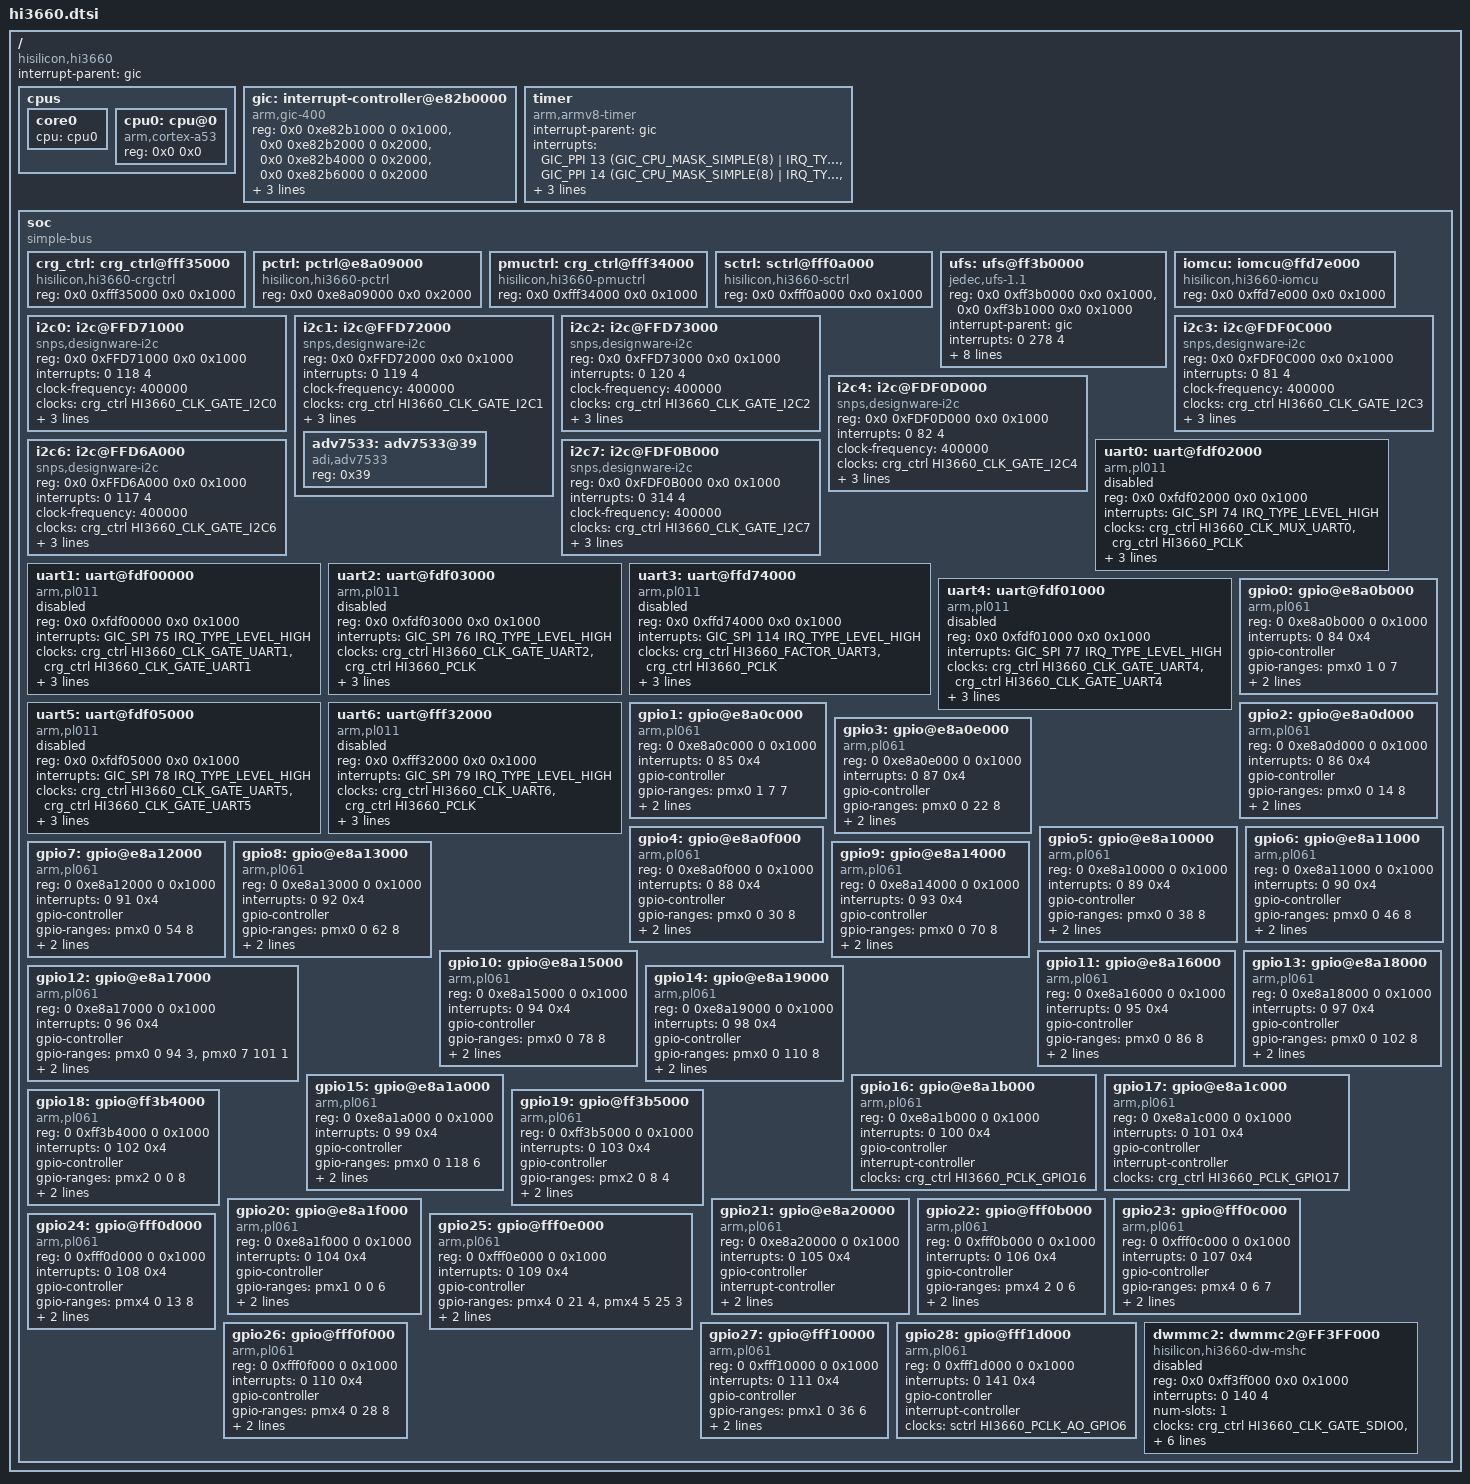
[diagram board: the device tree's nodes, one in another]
/*
 * dts file for Hisilicon Hi3660 SoC
 *
 * Copyright (C) 2016, Hisilicon Ltd.
 */

#include <dt-bindings/interrupt-controller/arm-gic.h>
#include <dt-bindings/clock/hi3660-clock.h>

/ {
	compatible = "hisilicon,hi3660";
	interrupt-parent = <&gic>;
	#address-cells = <2>;
	#size-cells = <2>;

	cpus {
		#address-cells = <2>;
		#size-cells = <0>;

		core0 {
			cpu = <&cpu0>;
		};

		cpu0: cpu@0 {
			compatible = "arm,cortex-a53", "arm,armv8";
			device_type = "cpu";
			reg = <0x0 0x0>;
		};
	};

	gic: interrupt-controller@e82b0000 {
		compatible = "arm,gic-400";
		reg = <0x0 0xe82b1000 0 0x1000>, /* GICD */
		      <0x0 0xe82b2000 0 0x2000>, /* GICC */
		      <0x0 0xe82b4000 0 0x2000>, /* GICH */
		      <0x0 0xe82b6000 0 0x2000>; /* GICV */
		#address-cells = <0>;
		#interrupt-cells = <3>;
		interrupt-controller;
		interrupts = <GIC_PPI 9 (GIC_CPU_MASK_SIMPLE(8) | IRQ_TYPE_LEVEL_HIGH)>;
	};

	timer {
		compatible = "arm,armv8-timer";
		interrupt-parent = <&gic>;
		interrupts = <GIC_PPI 13 (GIC_CPU_MASK_SIMPLE(8) | IRQ_TYPE_LEVEL_LOW)>,
			     <GIC_PPI 14 (GIC_CPU_MASK_SIMPLE(8) | IRQ_TYPE_LEVEL_LOW)>,
			     <GIC_PPI 11 (GIC_CPU_MASK_SIMPLE(8) | IRQ_TYPE_LEVEL_LOW)>,
			     <GIC_PPI 10 (GIC_CPU_MASK_SIMPLE(8) | IRQ_TYPE_LEVEL_LOW)>;
		clock-frequency = <1920000>;
	};

	soc {
		compatible = "simple-bus";
		#address-cells = <2>;
		#size-cells = <2>;
		ranges;

		crg_ctrl: crg_ctrl@fff35000 {
			compatible = "hisilicon,hi3660-crgctrl", "syscon";
			reg = <0x0 0xfff35000 0x0 0x1000>;
			#clock-cells = <1>;
		};

		pctrl: pctrl@e8a09000 {
			compatible = "hisilicon,hi3660-pctrl", "syscon";
			reg = <0x0 0xe8a09000 0x0 0x2000>;
			#clock-cells = <1>;
		};

		pmuctrl: crg_ctrl@fff34000 {
			compatible = "hisilicon,hi3660-pmuctrl", "syscon";
			reg = <0x0 0xfff34000 0x0 0x1000>;
			#clock-cells = <1>;
		};

		sctrl: sctrl@fff0a000 {
			compatible = "hisilicon,hi3660-sctrl", "syscon";
			reg = <0x0 0xfff0a000 0x0 0x1000>;
			#clock-cells = <1>;
		};

		ufs: ufs@ff3b0000 {
			compatible = "jedec,ufs-1.1", "hisilicon,hi3660-ufs";
			reg = <0x0 0xff3b0000 0x0 0x1000>,	/* 0: HCI standard */
			      <0x0 0xff3b1000 0x0 0x1000>;	/* 1: UFS SYS CTRL */
			interrupt-parent = <&gic>;
			interrupts = <0 278 4>;
			clocks = <&crg_ctrl HI3660_CLK_GATE_UFSIO_REF>,
				 <&crg_ctrl HI3660_CLK_GATE_UFSPHY_CFG>;
			clock-names = "clk_ref", "clk_phy";
			freq-table-hz = <0 0>, <0 0>;
			//vcc-supply = <&ldo15>;
			ufs-hi3660-use-rate-B;
			ufs-hi3660-broken-fastauto;
			ufs-hi3660-use-HS-GEAR3;
			ufs-hi3660-unipro-termination;
			ufs-hi3660-broken-clk-gate-bypass;
			status = "ok";
		};

		iomcu: iomcu@ffd7e000 {
			compatible = "hisilicon,hi3660-iomcu", "syscon";
			reg = <0x0 0xffd7e000 0x0 0x1000>;
			#clock-cells = <1>;
		};

		i2c0: i2c@FFD71000 {
			compatible = "snps,designware-i2c";
			reg = <0x0 0xFFD71000 0x0 0x1000>;
			interrupts = <0 118 4>;
                        #address-cells = <1>;
                        #size-cells = <0>;
			clock-frequency = <400000>;
			clocks = <&crg_ctrl HI3660_CLK_GATE_I2C0>;
			reset-reg-base = <0x0 0xFFD7E000 0x0 0x1000>;
			reset-controller-reg = <0x20 0x24 0X28 3>;
			pinctrl-names = "default";
			pinctrl-0 = <&i2c0_pmx_func>;
			status = "ok";
		};

		i2c1: i2c@FFD72000 {
			compatible = "snps,designware-i2c";
			reg = <0x0 0xFFD72000 0x0 0x1000>;
			interrupts = <0 119 4>;
                        #address-cells = <1>;
                        #size-cells = <0>;
			clock-frequency = <400000>;
			clocks = <&crg_ctrl HI3660_CLK_GATE_I2C1>;
			reset-reg-base = <0x0 0xFFD7E000 0x0 0x1000>;
			reset-controller-reg = <0x20 0x24 0X28 4>;
			pinctrl-names = "default";
			pinctrl-0 = <&i2c1_pmx_func>;
			status = "ok";

			adv7533: adv7533@39 {
				status = "ok";
				compatible = "adi,adv7533";
				reg = <0x39>;
				//v1p2-supply = <&ldo1>;
				//vdd-supply = <&ldo3>;
				//interrupt-parent = <&gpio1>;
				//interrupts = <1 2>;
				//pd-gpio = <&gpio5 1 0>;
				//sel-gpio = <&gpio2 4 0>;
				//adi,dsi-lanes = <4>;
				//adi,disable-timing-generator;
			};
		};

		i2c2: i2c@FFD73000 {
			compatible = "snps,designware-i2c";
			reg = <0x0 0xFFD73000 0x0 0x1000>;
			interrupts = <0 120 4>;
                        #address-cells = <1>;
                        #size-cells = <0>;
			clock-frequency = <400000>;
			clocks = <&crg_ctrl HI3660_CLK_GATE_I2C2>;
			reset-reg-base = <0x0 0xFFD7E000 0x0 0x1000>;
			reset-controller-reg = <0x20 0x24 0X28 5>;
			pinctrl-names = "default";
			pinctrl-0 = <&i2c2_pmx_func>;
			status = "ok";
		};

		i2c3: i2c@FDF0C000 {
			compatible = "snps,designware-i2c";
			reg = <0x0 0xFDF0C000 0x0 0x1000>;
			interrupts = <0 81 4>;
                        #address-cells = <1>;
                        #size-cells = <0>;
			clock-frequency = <400000>;
			clocks = <&crg_ctrl HI3660_CLK_GATE_I2C3>;
			reset-reg-base = <0x0 0xFFF35000 0x0 0x1000>;
			reset-controller-reg = <0x78 0x7c 0x80 7>;
			pinctrl-names = "default";
			pinctrl-0 = <&i2c3_pmx_func>;
			status = "ok";
		};

		i2c4: i2c@FDF0D000 {
			compatible = "snps,designware-i2c";
			reg = <0x0 0xFDF0D000 0x0 0x1000>;
			interrupts = <0 82 4>;
                        #address-cells = <1>;
                        #size-cells = <0>;
			clock-frequency = <400000>;
			clocks = <&crg_ctrl HI3660_CLK_GATE_I2C4>;
			reset-reg-base = <0x0 0xFFF35000 0x0 0x1000>;
			reset-controller-reg = <0x78 0x7c 0x80 27>;
			pinctrl-names = "default";
			pinctrl-0 = <&i2c4_pmx_func>;
			status = "ok";
		};

		i2c6: i2c@FFD6A000 {
			compatible = "snps,designware-i2c";
			reg = <0x0 0xFFD6A000 0x0 0x1000>;
			interrupts = <0 117 4>;
                        #address-cells = <1>;
                        #size-cells = <0>;
			clock-frequency = <400000>;
			clocks = <&crg_ctrl HI3660_CLK_GATE_I2C6>;
			reset-reg-base = <0x0 0xFFD7E000 0x0 0x1000>;
			reset-controller-reg = <0x20 0x24 0X28 27>;
			pinctrl-names = "default";
			pinctrl-0 = <&i2c6_pmx_func>;
			status = "ok";
		};

		i2c7: i2c@FDF0B000 {
			compatible = "snps,designware-i2c";
			reg = <0x0 0xFDF0B000 0x0 0x1000>;
			interrupts = <0 314 4>;
                        #address-cells = <1>;
                        #size-cells = <0>;
			clock-frequency = <400000>;
			clocks = <&crg_ctrl HI3660_CLK_GATE_I2C7>;
			reset-reg-base = <0x0 0xFFF35000 0x0 0x1000>;
			reset-controller-reg = <0x60 0x64 0x68 14>;
			pinctrl-names = "default";
			pinctrl-0 = <&i2c7_pmx_func>;
			status = "ok";
		};

		uart0: uart@fdf02000 {
			compatible = "arm,pl011", "arm,primecell";
			reg = <0x0 0xfdf02000 0x0 0x1000>;
			interrupts = <GIC_SPI 74 IRQ_TYPE_LEVEL_HIGH>;
			clocks = <&crg_ctrl HI3660_CLK_MUX_UART0>,
				 <&crg_ctrl HI3660_PCLK>;
			clock-names = "uartclk", "apb_pclk";
			reset-enable-flag = <0>;
			reset-reg-base = <0x0 0xFFF35000 0x0 0x1000>; /* PERI_CRG */
			reset-controller-reg = <0x78 0x7c 0x80 10>;
			status = "disabled";
		};

		uart1: uart@fdf00000 {
			compatible = "arm,pl011", "arm,primecell";
			reg = <0x0 0xfdf00000 0x0 0x1000>;
			interrupts = <GIC_SPI 75 IRQ_TYPE_LEVEL_HIGH>;
			clocks = <&crg_ctrl HI3660_CLK_GATE_UART1>,
				 <&crg_ctrl HI3660_CLK_GATE_UART1>;
			clock-names = "uartclk", "apb_pclk";
			reset-enable-flag = <0>;
			reset-reg-base = <0x0 0xFFF35000 0x0 0x1000>; /* PERI_CRG */
			reset-controller-reg = <0x78 0x7c 0x80 11>;
			status = "disabled";
		};

		uart2: uart@fdf03000 {
			compatible = "arm,pl011", "arm,primecell";
			reg = <0x0 0xfdf03000 0x0 0x1000>;
			interrupts = <GIC_SPI 76 IRQ_TYPE_LEVEL_HIGH>;
			clocks = <&crg_ctrl HI3660_CLK_GATE_UART2>,
				 <&crg_ctrl HI3660_PCLK>;
			clock-names = "uartclk", "apb_pclk";
			reset-enable-flag = <0>;
			reset-reg-base = <0x0 0xFFF35000 0x0 0x1000>; /* PERI_CRG */
			reset-controller-reg = <0x78 0x7c 0x80 12>;
			status = "disabled";
		};

		uart3: uart@ffd74000 {
			compatible = "arm,pl011", "arm,primecell";
			reg = <0x0 0xffd74000 0x0 0x1000>;
			interrupts = <GIC_SPI 114 IRQ_TYPE_LEVEL_HIGH>;
			clocks = <&crg_ctrl HI3660_FACTOR_UART3>,
				 <&crg_ctrl HI3660_PCLK>;
			clock-names = "uartclk", "apb_pclk";
			reset-enable-flag = <0>;
			reset-reg-base = <0x0 0xFFD7E000 0x0 0x1000>; /* IOMCU_CONFIG */
			reset-controller-reg = <0x20 0x24 0x28 11>;
			status = "disabled";
	        };

		uart4: uart@fdf01000 {
			compatible = "arm,pl011", "arm,primecell";
			reg = <0x0 0xfdf01000 0x0 0x1000>;
			interrupts = <GIC_SPI 77 IRQ_TYPE_LEVEL_HIGH>;
			clocks = <&crg_ctrl HI3660_CLK_GATE_UART4>,
				 <&crg_ctrl HI3660_CLK_GATE_UART4>;
			clock-names = "uartclk", "apb_pclk";
			reset-enable-flag = <0>;
			reset-reg-base = <0x0 0xFFF35000 0x0 0x1000>; /* PERI_CRG */
			reset-controller-reg = <0x78 0x7c 0x80 14>;
			status = "disabled";
		};

		uart5: uart@fdf05000 {
			compatible = "arm,pl011", "arm,primecell";
			reg = <0x0 0xfdf05000 0x0 0x1000>;
			interrupts = <GIC_SPI 78 IRQ_TYPE_LEVEL_HIGH>;
			clocks = <&crg_ctrl HI3660_CLK_GATE_UART5>,
				 <&crg_ctrl HI3660_CLK_GATE_UART5>;
			clock-names = "uartclk", "apb_pclk";
			reset-enable-flag = <0>;
			reset-reg-base = <0x0 0xFFF35000 0x0 0x1000>; /* PERI_CRG */
			reset-controller-reg = <0x78 0x7c 0x80 15>;
			status = "disabled";
		};

		uart6: uart@fff32000 {
			compatible = "arm,pl011", "arm,primecell";
			reg = <0x0 0xfff32000 0x0 0x1000>;
			interrupts = <GIC_SPI 79 IRQ_TYPE_LEVEL_HIGH>;
			clocks = <&crg_ctrl HI3660_CLK_UART6>,
				 <&crg_ctrl HI3660_PCLK>;
			clock-names = "uartclk", "apb_pclk";
			reset-enable-flag = <0>;
			reset-reg-base = <0x0 0xFFF0A000 0x0 0x1000>; /* SCTRL */
			reset-controller-reg = <0x504 0x508 0x50c 9>;
			status = "disabled";
		};

		gpio0: gpio@e8a0b000 {
			compatible = "arm,pl061", "arm,primecell", "arm,primecell0";
			reg = <0 0xe8a0b000 0 0x1000>;
			interrupts = <0 84 0x4>;
			gpio-controller;
			#gpio-cells = <2>;
			gpio-ranges = <&pmx0 1 0 7>;
			interrupt-controller;
			#interrupt-cells = <2>;
			clocks = <&crg_ctrl HI3660_PCLK_GPIO0>;
			clock-names = "apb_pclk";
			status = "ok";
		};

		gpio1: gpio@e8a0c000 {
			compatible = "arm,pl061", "arm,primecell", "arm,primecell1";
			reg = <0 0xe8a0c000 0 0x1000>;
			interrupts = <0 85 0x4>;
			gpio-controller;
			#gpio-cells = <2>;
			gpio-ranges = <&pmx0 1 7 7>;
			interrupt-controller;
			#interrupt-cells = <2>;
			clocks = <&crg_ctrl HI3660_PCLK_GPIO1>;
			clock-names = "apb_pclk";
			status = "ok";
		};

		gpio2: gpio@e8a0d000 {
			compatible = "arm,pl061", "arm,primecell", "arm,primecell2";
			reg = <0 0xe8a0d000 0 0x1000>;
			interrupts = <0 86 0x4>;
			gpio-controller;
			#gpio-cells = <2>;
			gpio-ranges = <&pmx0 0 14 8>;
			interrupt-controller;
			#interrupt-cells = <2>;
			clocks = <&crg_ctrl HI3660_PCLK_GPIO2>;
			clock-names = "apb_pclk";
			status = "ok";
		};

		gpio3: gpio@e8a0e000 {
			compatible = "arm,pl061", "arm,primecell", "arm,primecell3";
			reg = <0 0xe8a0e000 0 0x1000>;
			interrupts = <0 87 0x4>;
			gpio-controller;
			#gpio-cells = <2>;
			gpio-ranges = <&pmx0 0 22 8>;
			interrupt-controller;
			#interrupt-cells = <2>;
			clocks = <&crg_ctrl HI3660_PCLK_GPIO3>;
			clock-names = "apb_pclk";
			status = "ok";
		};

		gpio4: gpio@e8a0f000 {
			compatible = "arm,pl061", "arm,primecell", "arm,primecell4";
			reg = <0 0xe8a0f000 0 0x1000>;
			interrupts = <0 88 0x4>;
			gpio-controller;
			#gpio-cells = <2>;
			gpio-ranges = <&pmx0 0 30 8>;
			interrupt-controller;
			#interrupt-cells = <2>;
			clocks = <&crg_ctrl HI3660_PCLK_GPIO4>;
			clock-names = "apb_pclk";
			status = "ok";
		};

		gpio5: gpio@e8a10000 {
			compatible = "arm,pl061", "arm,primecell", "arm,primecell5";
			reg = <0 0xe8a10000 0 0x1000>;
			interrupts = <0 89 0x4>;
			gpio-controller;
			#gpio-cells = <2>;
			gpio-ranges = <&pmx0 0 38 8>;
			interrupt-controller;
			#interrupt-cells = <2>;
			clocks = <&crg_ctrl HI3660_PCLK_GPIO5>;
			clock-names = "apb_pclk";
			status = "ok";
		};

		gpio6: gpio@e8a11000 {
			compatible = "arm,pl061", "arm,primecell", "arm,primecell6";
			reg = <0 0xe8a11000 0 0x1000>;
			interrupts = <0 90 0x4>;
			gpio-controller;
			#gpio-cells = <2>;
			gpio-ranges = <&pmx0 0 46 8>;
			interrupt-controller;
			#interrupt-cells = <2>;
			clocks = <&crg_ctrl HI3660_PCLK_GPIO6>;
			clock-names = "apb_pclk";
			status = "ok";
		};

		gpio7: gpio@e8a12000 {
			compatible = "arm,pl061", "arm,primecell", "arm,primecell7";
			reg = <0 0xe8a12000 0 0x1000>;
			interrupts = <0 91 0x4>;
			gpio-controller;
			#gpio-cells = <2>;
			gpio-ranges = <&pmx0 0 54 8>;
			interrupt-controller;
			#interrupt-cells = <2>;
			clocks = <&crg_ctrl HI3660_PCLK_GPIO7>;
			clock-names = "apb_pclk";
			status = "ok";
		};

		gpio8: gpio@e8a13000 {
			compatible = "arm,pl061", "arm,primecell", "arm,primecell8";
			reg = <0 0xe8a13000 0 0x1000>;
			interrupts = <0 92 0x4>;
			gpio-controller;
			#gpio-cells = <2>;
			gpio-ranges = <&pmx0 0 62 8>;
			interrupt-controller;
			#interrupt-cells = <2>;
			clocks = <&crg_ctrl HI3660_PCLK_GPIO8>;
			clock-names = "apb_pclk";
			status = "ok";
		};

		gpio9: gpio@e8a14000 {
			compatible = "arm,pl061", "arm,primecell", "arm,primecell9";
			reg = <0 0xe8a14000 0 0x1000>;
			interrupts = <0 93 0x4>;
			gpio-controller;
			#gpio-cells = <2>;
			gpio-ranges = <&pmx0 0 70 8>;
			interrupt-controller;
			#interrupt-cells = <2>;
			clocks = <&crg_ctrl HI3660_PCLK_GPIO9>;
			clock-names = "apb_pclk";
			status = "ok";
		};

		gpio10: gpio@e8a15000 {
			compatible = "arm,pl061", "arm,primecell", "arm,primecell10";
			reg = <0 0xe8a15000 0 0x1000>;
			interrupts = <0 94 0x4>;
			gpio-controller;
			#gpio-cells = <2>;
			gpio-ranges = <&pmx0 0 78 8>;
			interrupt-controller;
			#interrupt-cells = <2>;
			clocks = <&crg_ctrl HI3660_PCLK_GPIO10>;
			clock-names = "apb_pclk";
			status = "ok";
		};

		gpio11: gpio@e8a16000 {
			compatible = "arm,pl061", "arm,primecell", "arm,primecell11";
			reg = <0 0xe8a16000 0 0x1000>;
			interrupts = <0 95 0x4>;
			gpio-controller;
			#gpio-cells = <2>;
			gpio-ranges = <&pmx0 0 86 8>;
			interrupt-controller;
			#interrupt-cells = <2>;
			clocks = <&crg_ctrl HI3660_PCLK_GPIO11>;
			clock-names = "apb_pclk";
			status = "ok";
		};

		gpio12: gpio@e8a17000 {
			compatible = "arm,pl061", "arm,primecell", "arm,primecell12";
			reg = <0 0xe8a17000 0 0x1000>;
			interrupts = <0 96 0x4>;
			gpio-controller;
			#gpio-cells = <2>;
			gpio-ranges = <&pmx0 0 94 3 &pmx0 7 101 1>;
			interrupt-controller;
			#interrupt-cells = <2>;
			clocks = <&crg_ctrl HI3660_PCLK_GPIO12>;
			clock-names = "apb_pclk";
			status = "ok";
		};

		gpio13: gpio@e8a18000 {
			compatible = "arm,pl061", "arm,primecell", "arm,primecell13";
			reg = <0 0xe8a18000 0 0x1000>;
			interrupts = <0 97 0x4>;
			gpio-controller;
			#gpio-cells = <2>;
			gpio-ranges = <&pmx0 0 102 8>;
			interrupt-controller;
			#interrupt-cells = <2>;
			clocks = <&crg_ctrl HI3660_PCLK_GPIO13>;
			clock-names = "apb_pclk";
			status = "ok";
		};

		gpio14: gpio@e8a19000 {
			compatible = "arm,pl061", "arm,primecell", "arm,primecell14";
			reg = <0 0xe8a19000 0 0x1000>;
			interrupts = <0 98 0x4>;
			gpio-controller;
			#gpio-cells = <2>;
			gpio-ranges = <&pmx0 0 110 8>;
			interrupt-controller;
			#interrupt-cells = <2>;
			clocks = <&crg_ctrl HI3660_PCLK_GPIO14>;
			clock-names = "apb_pclk";
			status = "ok";
		};

		gpio15: gpio@e8a1a000 {
			compatible = "arm,pl061", "arm,primecell", "arm,primecell15";
			reg = <0 0xe8a1a000 0 0x1000>;
			interrupts = <0 99 0x4>;
			gpio-controller;
			#gpio-cells = <2>;
			gpio-ranges = <&pmx0 0 118 6>;
			interrupt-controller;
			#interrupt-cells = <2>;
			clocks = <&crg_ctrl HI3660_PCLK_GPIO15>;
			clock-names = "apb_pclk";
			status = "ok";
		};

		gpio16: gpio@e8a1b000 {
			compatible = "arm,pl061", "arm,primecell", "arm,primecell16";
			reg = <0 0xe8a1b000 0 0x1000>;
			interrupts = <0 100 0x4>;
			gpio-controller;
			#gpio-cells = <2>;
			interrupt-controller;
			#interrupt-cells = <2>;
			clocks = <&crg_ctrl HI3660_PCLK_GPIO16>;
			clock-names = "apb_pclk";
			status = "ok";
		};

		gpio17: gpio@e8a1c000 {
			compatible = "arm,pl061", "arm,primecell", "arm,primecell17";
			reg = <0 0xe8a1c000 0 0x1000>;
			interrupts = <0 101 0x4>;
			gpio-controller;
			#gpio-cells = <2>;
			interrupt-controller;
			#interrupt-cells = <2>;
			clocks = <&crg_ctrl HI3660_PCLK_GPIO17>;
			clock-names = "apb_pclk";
			status = "ok";
		};

		gpio18: gpio@ff3b4000 {
			compatible = "arm,pl061", "arm,primecell", "arm,primecell18";
			reg = <0 0xff3b4000 0 0x1000>;
			interrupts = <0 102 0x4>;
			gpio-controller;
			#gpio-cells = <2>;
			gpio-ranges = <&pmx2 0 0 8>;
			interrupt-controller;
			#interrupt-cells = <2>;
			clocks = <&crg_ctrl HI3660_PCLK_GPIO18>;
			clock-names = "apb_pclk";
			status = "ok";
		};

		gpio19: gpio@ff3b5000 {
			compatible = "arm,pl061", "arm,primecell", "arm,primecell19";
			reg = <0 0xff3b5000 0 0x1000>;
			interrupts = <0 103 0x4>;
			gpio-controller;
			#gpio-cells = <2>;
			gpio-ranges = <&pmx2 0 8 4>;
			interrupt-controller;
			#interrupt-cells = <2>;
			clocks = <&crg_ctrl HI3660_PCLK_GPIO19>;
			clock-names = "apb_pclk";
			status = "ok";
		};

		gpio20: gpio@e8a1f000 {
			compatible = "arm,pl061", "arm,primecell", "arm,primecell20";
			reg = <0 0xe8a1f000 0 0x1000>;
			interrupts = <0 104 0x4>;
			gpio-controller;
			#gpio-cells = <2>;
			gpio-ranges = <&pmx1 0 0 6>;
			interrupt-controller;
			#interrupt-cells = <2>;
			clocks = <&crg_ctrl HI3660_PCLK_GPIO20>;
			clock-names = "apb_pclk";
			status = "ok";
		};

		gpio21: gpio@e8a20000 {
			compatible = "arm,pl061", "arm,primecell", "arm,primecell21";
			reg = <0 0xe8a20000 0 0x1000>;
			interrupts = <0 105 0x4>;
			gpio-controller;
			#gpio-cells = <2>;
			interrupt-controller;
			#interrupt-cells = <2>;
			gpio-ranges = <&pmx3 0 0 6>;
			clocks = <&crg_ctrl HI3660_PCLK_GPIO21>;
			clock-names = "apb_pclk";
			status = "ok";
		};

		gpio22: gpio@fff0b000 {
			compatible = "arm,pl061", "arm,primecell", "arm,primecell22";
			reg = <0 0xfff0b000 0 0x1000>;
			interrupts = <0 106 0x4>;
			gpio-controller;
			#gpio-cells = <2>;
			/* GPIO176 */
			gpio-ranges = <&pmx4 2 0 6>;
			interrupt-controller;
			#interrupt-cells = <2>;
			clocks = <&sctrl HI3660_PCLK_AO_GPIO0>;
			clock-names = "apb_pclk";
			status = "ok";
		};

		gpio23: gpio@fff0c000 {
			compatible = "arm,pl061", "arm,primecell", "arm,primecell23";
			reg = <0 0xfff0c000 0 0x1000>;
			interrupts = <0 107 0x4>;
			gpio-controller;
			#gpio-cells = <2>;
			/* GPIO184 */
			gpio-ranges = <&pmx4 0 6 7>;
			interrupt-controller;
			#interrupt-cells = <2>;
			clocks = <&sctrl HI3660_PCLK_AO_GPIO1>;
			clock-names = "apb_pclk";
			status = "ok";
		};

		 gpio24: gpio@fff0d000 {
			compatible = "arm,pl061", "arm,primecell", "hisi,poweroff", "arm,primecell24";
			reg = <0 0xfff0d000 0 0x1000>;
			interrupts = <0 108 0x4>;
			gpio-controller;
			#gpio-cells = <2>;
			/* GPIO192 */
			gpio-ranges = <&pmx4 0 13 8>;
			interrupt-controller;
			#interrupt-cells = <2>;
			clocks = <&sctrl HI3660_PCLK_AO_GPIO2>;
			clock-names = "apb_pclk";
			status = "ok";
		};

		gpio25: gpio@fff0e000 {
			compatible = "arm,pl061", "arm,primecell", "arm,primecell25";
			reg = <0 0xfff0e000 0 0x1000>;
			interrupts = <0 109 0x4>;
			gpio-controller;
			#gpio-cells = <2>;
			/* GPIO200 */
			gpio-ranges = <&pmx4 0 21 4 &pmx4 5 25 3>;
			interrupt-controller;
			#interrupt-cells = <2>;
			clocks = <&sctrl HI3660_PCLK_AO_GPIO3>;
			clock-names = "apb_pclk";
			status = "ok";
		};

		gpio26: gpio@fff0f000 {
			compatible = "arm,pl061", "arm,primecell", "arm,primecell26";
			reg = <0 0xfff0f000 0 0x1000>;
			interrupts = <0 110 0x4>;
			gpio-controller;
			#gpio-cells = <2>;
			/* GPIO208 */
			gpio-ranges = <&pmx4 0 28 8>;
			interrupt-controller;
			#interrupt-cells = <2>;
			clocks = <&sctrl HI3660_PCLK_AO_GPIO4>;
			clock-names = "apb_pclk";
			status = "ok";
		};

		gpio27: gpio@fff10000 {
			compatible = "arm,pl061", "arm,primecell", "arm,primecell27";
			reg = <0 0xfff10000 0 0x1000>;
			interrupts = <0 111 0x4>;
			gpio-controller;
			#gpio-cells = <2>;
			/* GPIO216 */
			gpio-ranges = <&pmx1 0 36 6>;
			interrupt-controller;
			#interrupt-cells = <2>;
			clocks = <&sctrl HI3660_PCLK_AO_GPIO5>;
			clock-names = "apb_pclk";
			status = "ok";
		};

		gpio28: gpio@fff1d000 {
			compatible = "arm,pl061", "arm,primecell", "arm,primecell28";
			reg = <0 0xfff1d000 0 0x1000>;
			interrupts = <0 141 0x4>;
			gpio-controller;
			#gpio-cells = <2>;
			interrupt-controller;
			#interrupt-cells = <2>;
			clocks = <&sctrl HI3660_PCLK_AO_GPIO6>;
			clock-names = "apb_pclk";
			status = "ok";
		};

		/* SDIO */
		dwmmc2: dwmmc2@FF3FF000 {
			compatible = "hisilicon,hi3660-dw-mshc";
			reg = <0x0 0xff3ff000 0x0 0x1000>;
			interrupts = <0 140 4>;
			num-slots = <1>;
			clocks = <&crg_ctrl HI3660_CLK_GATE_SDIO0>,
				 <&crg_ctrl HI3660_HCLK_GATE_SDIO0>;
			clock-names = "ciu", "biu";
			card-detect-delay = <200>;
			supports-highspeed;
			keep-power-in-suspend;
			pinctrl-names = "default";
			pinctrl-0 = <>;
			pinctrl-1 = <>;
			status = "disabled";
		};
	};
};
